VERSION "HNPBNNNYYNYNNYYNNNNNNNNNNNNNNNYNNNNYNNNNNN/4/%%%/4/'%**4NNN///"

NS_ :

BS_:

BU_: Engine Gateway DisplayEng

BO_ 1307 NM_Engine: 2 Engine
 SG_ SleepInd : 12|1@1+ (1,0) [0|1] "" Vector__XXX

BO_ 1306 NM_Gateway_Motbus: 2 Gateway
 SG_ SleepInd : 12|1@1+ (1,0) [0|1] "" Vector__XXX

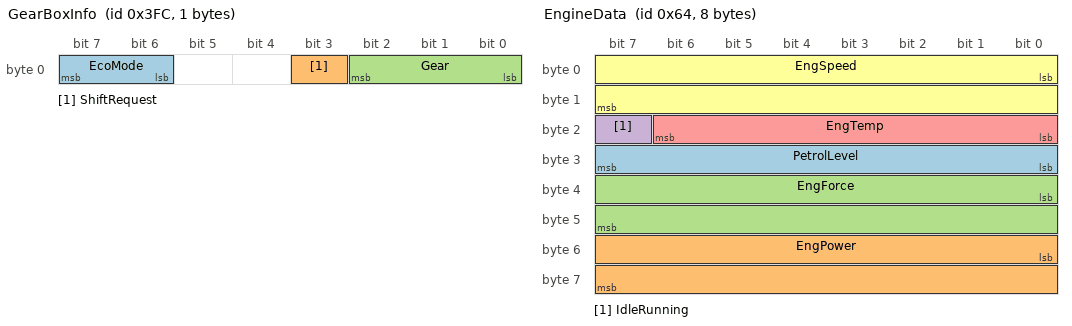
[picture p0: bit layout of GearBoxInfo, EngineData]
BO_ 1020 GearBoxInfo: 1 Engine
 SG_ EcoMode : 6|2@1+ (1,0) [0|1] "" Vector__XXX
 SG_ ShiftRequest : 3|1@1+ (1,0) [0|0] "" Vector__XXX
 SG_ Gear : 0|3@1+ (1,0) [0|8] ""  DisplayEng

BO_ 101 EngineStatus: 1 Engine
 SG_ ErrorCode : 2|6@1+ (1,0) [0|0] "" Vector__XXX
 SG_ Status : 0|2@1+ (1,0) [0|0] "" Vector__XXX

BO_ 102 EngineDataIEEE: 8 Engine
 SG_ EngSpeed : 0|32@1- (1,0) [0|8000] "rpm" Vector__XXX
 SG_ EngForce : 32|32@1- (1,0) [0|0] "N" Vector__XXX

BO_ 100 EngineData: 8 Engine
 SG_ PetrolLevel : 24|8@1+ (1,0) [0|45] "l" Vector__XXX
 SG_ EngPower : 48|16@1+ (0.01,0) [0|150] "kW" Vector__XXX
 SG_ EngForce : 32|16@1+ (1,0) [0|0] "N" Vector__XXX
 SG_ IdleRunning : 23|1@1+ (1,0) [0|0] ""  DisplayEng
 SG_ EngTemp : 16|7@1+ (2,-50) [-50|150] "degC"  DisplayEng
 SG_ EngSpeed : 0|16@1+ (1,0) [0|8000] "rpm"  DisplayEng

BO_ 1544 DiagResponse_Motor: 8 Engine

BO_ 1537 DiagRequest_Motor: 8 Gateway

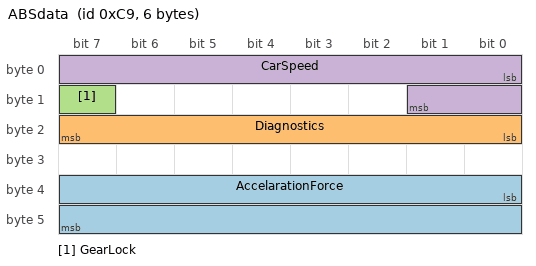
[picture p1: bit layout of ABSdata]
BO_ 201 ABSdata: 6 Engine
 SG_ AccelarationForce : 32|16@1+ (1,-10000) [0|0] "N" Vector__XXX
 SG_ Diagnostics : 16|8@1+ (1,0) [0|0] "" Vector__XXX
 SG_ GearLock : 15|1@1+ (1,0) [0|0] "" Vector__XXX
 SG_ CarSpeed : 0|10@1+ (0.5,0) [0|300] "mp/h"  DisplayEng

CM_ "CAN communication matrix for body electronics
*******************************************************

implemented: turn lights, warning lights, windows


";
BA_DEF_ BO_  "GenMsgNrOfRepetitions" INT 1 999999;
BA_DEF_ BO_  "GenMsgDelayTime" INT 1 1000;
BA_DEF_ BO_  "GenMsgCycleTime" INT 2 50000;
BA_DEF_ BO_  "GenMsgSendType" ENUM  "cyclic","spontan","cyclicIfActive","spontanWithDelay","cyclicAndSpontan","cyclicAndSpontanWithDelay","spontanWithRepetition","cyclicIfActiveAndSpontanWD";
BA_DEF_ SG_  "GenSigStartValue" FLOAT -100000000000 100000000000;
BA_DEF_ SG_  "GenSigEnvVarType" ENUM  "int","float","undef";
BA_DEF_DEF_  "GenMsgNrOfRepetitions" 1;
BA_DEF_DEF_  "GenMsgDelayTime" 1;
BA_DEF_DEF_  "GenMsgCycleTime" 2;
BA_DEF_DEF_  "GenMsgSendType" "";
BA_DEF_DEF_  "GenSigStartValue" 0;
BA_DEF_DEF_  "GenSigEnvVarType" "undef";
BA_ "GenMsgSendType" BO_ 1307 0;
BA_ "GenMsgSendType" BO_ 1306 0;
BA_ "GenMsgSendType" BO_ 1544 1;
BA_ "GenMsgSendType" BO_ 201 0;
BA_ "GenMsgCycleTime" BO_ 201 50;
BA_ "GenSigEnvVarType" SG_ 1306 SleepInd 0;
BA_ "GenSigEnvVarType" SG_ 1020 EcoMode 0;
BA_ "GenSigEnvVarType" SG_ 1020 ShiftRequest 0;
BA_ "GenSigEnvVarType" SG_ 1020 Gear 0;
BA_ "GenSigEnvVarType" SG_ 101 ErrorCode 0;
BA_ "GenSigEnvVarType" SG_ 101 Status 0;
BA_ "GenSigEnvVarType" SG_ 102 EngForce 0;
BA_ "GenSigEnvVarType" SG_ 100 PetrolLevel 0;
BA_ "GenSigEnvVarType" SG_ 100 EngPower 1;
BA_ "GenSigEnvVarType" SG_ 100 EngForce 0;
BA_ "GenSigEnvVarType" SG_ 100 IdleRunning 0;
BA_ "GenSigEnvVarType" SG_ 100 EngTemp 0;
BA_ "GenSigEnvVarType" SG_ 100 EngSpeed 0;
BA_ "GenSigEnvVarType" SG_ 201 AccelarationForce 0;
BA_ "GenSigEnvVarType" SG_ 201 Diagnostics 0;
BA_ "GenSigEnvVarType" SG_ 201 GearLock 0;
BA_ "GenSigEnvVarType" SG_ 201 CarSpeed 1;
VAL_ 1020 ShiftRequest 1 "Shift_Request_On" 0 "Shift_Request_Off" ;
VAL_ 1020 Gear 1 "Gear_1" 2 "Gear_2" 3 "Gear_3" 4 "Gear_4" 5 "Gear_5" ;
VAL_ 101 Status 3 "Error" 2 "GoSleep" 1 "Running" 0 "WakeUp" ;
VAL_ 100 IdleRunning 0 "Running" 1 "Idle" ;
VAL_ 201 GearLock 1 "Gear_Lock_On" 0 "Gear_Lock_Off" ;
SIG_VALTYPE_ 102 EngSpeed : 1;
SIG_VALTYPE_ 102 EngForce : 1;
